AUTOSAR XML (schema 4-2-2)
package /AUTOLIV/SoftwareComponents/SCM
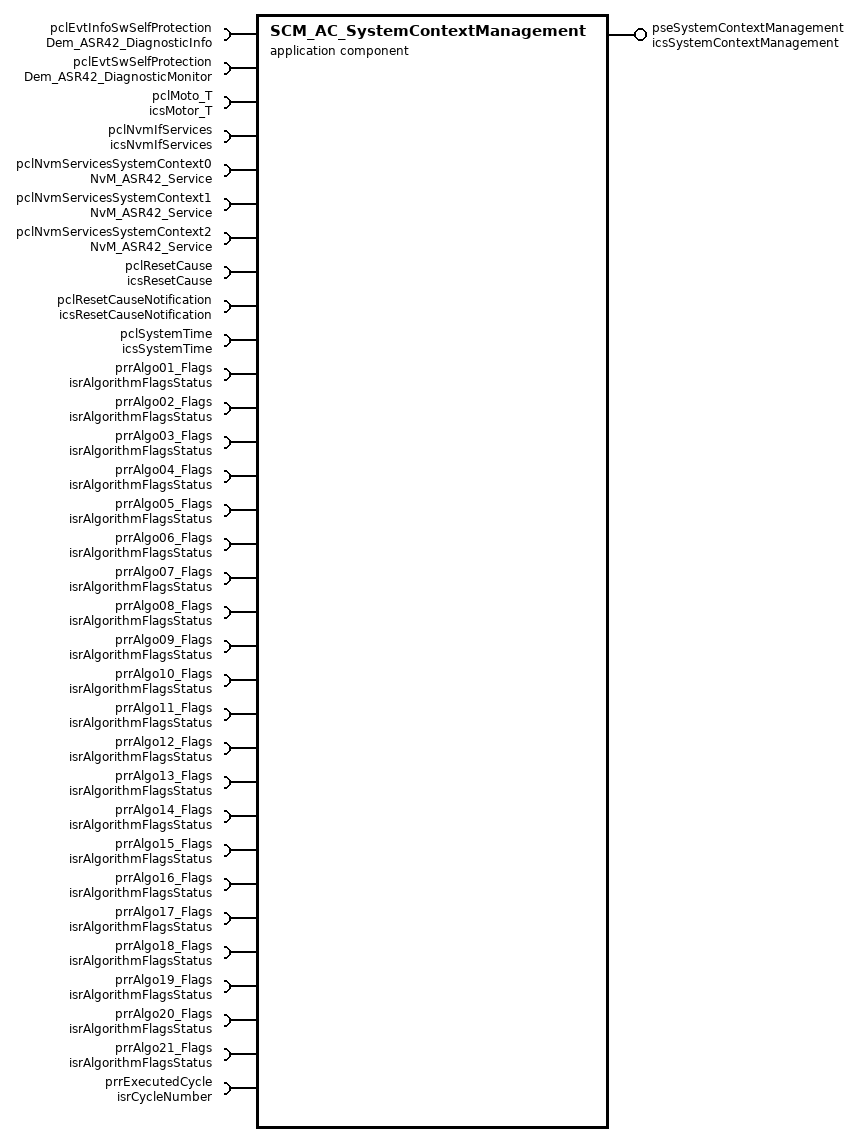
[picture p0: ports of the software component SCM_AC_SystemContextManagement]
  application sw component type SCM_AC_SystemContextManagement: category=SWC
    32 x require port:
      pclEvtInfoSwSelfProtection: required-interface=Dem_ASR42_DiagnosticInfo
        required-com-specs:
          GetEventStatus
          GetEventFailed
          GetEventTested
          GetDTCOfEvent
          GetFaultDetectionCounter
          GetEventFreezeFrameData
          GetEventExtendedDataRecord
      pclEvtSwSelfProtection: required-com-specs=[SetEventStatus, ResetEventStatus, PrestoreFreezeFrame, ClearPrestoredFreezeFrame], required-interface=Dem_ASR42_DiagnosticMonitor
      pclMoto_T: required-com-specs=[GetDeficiencyLevel, InitializeDeficiencyLevel], required-interface=icsMotor_T
      pclNvmIfServices: required-com-specs=[GetNvmBlockStatus, GetNvmBlockLength, SynchronousRecord], required-interface=icsNvmIfServices
      pclNvmServicesSystemContext0: required-interface=NvM_ASR42_Service
        required-com-specs:
          GetErrorStatus
          SetDataIndex
          GetDataIndex
          SetRamBlockStatus
          ReadBlock
          WriteBlock
          RestoreBlockDefaults
          EraseBlock
          InvalidateNvBlock
      pclNvmServicesSystemContext1: required-interface=NvM_ASR42_Service
        required-com-specs:
          GetErrorStatus
          SetDataIndex
          GetDataIndex
          SetRamBlockStatus
          ReadBlock
          WriteBlock
          RestoreBlockDefaults
          EraseBlock
          InvalidateNvBlock
      pclNvmServicesSystemContext2: required-interface=NvM_ASR42_Service
        required-com-specs:
          GetErrorStatus
          SetDataIndex
          GetDataIndex
          SetRamBlockStatus
          ReadBlock
          WriteBlock
          RestoreBlockDefaults
          EraseBlock
          InvalidateNvBlock
      pclResetCause: client-com-spec=GetResetCause, required-interface=icsResetCause
      pclResetCauseNotification: client-com-spec=NotifyResetCause, required-interface=icsResetCauseNotification
      pclSystemTime: required-com-specs=[ReadRelativeSystemTime, WriteRelativeSystemTime, ReadAbsoluteSystemTime, WriteAbsoluteSystemTime], required-interface=icsSystemTime
      prrAlgo01_Flags: required-interface=isrAlgorithmFlagsStatus
        required-com-specs:
          data-element=b8TriggerFlag, uses-end-to-end-protection=0, init-value=constant-reference=APPLINIT_KB8_ALGO_FLAG_FALSE
          data-element=b8InterruptFlag, uses-end-to-end-protection=0, init-value=constant-reference=APPLINIT_KB8_ALGO_FLAG_FALSE
          data-element=b8PreActivationFlag, uses-end-to-end-protection=0, init-value=constant-reference=APPLINIT_KB8_ALGO_FLAG_FALSE
          data-element=b8PreConditionsFlag, uses-end-to-end-protection=0, init-value=constant-reference=APPLINIT_KB8_ALGO_FLAG_FALSE
          data-element=u8TriggeringSource, uses-end-to-end-protection=0, init-value=constant-reference=APPLINIT_KU8_TRIGGERING_SOURCE_NO
      prrAlgo02_Flags: required-interface=isrAlgorithmFlagsStatus
        required-com-specs:
          data-element=b8TriggerFlag, uses-end-to-end-protection=0, init-value=constant-reference=APPLINIT_KB8_ALGO_FLAG_FALSE
          data-element=b8InterruptFlag, uses-end-to-end-protection=0, init-value=constant-reference=APPLINIT_KB8_ALGO_FLAG_FALSE
          data-element=b8PreActivationFlag, uses-end-to-end-protection=0, init-value=constant-reference=APPLINIT_KB8_ALGO_FLAG_FALSE
          data-element=b8PreConditionsFlag, uses-end-to-end-protection=0, init-value=constant-reference=APPLINIT_KB8_ALGO_FLAG_FALSE
          data-element=u8TriggeringSource, uses-end-to-end-protection=0, init-value=constant-reference=APPLINIT_KU8_TRIGGERING_SOURCE_NO
      prrAlgo03_Flags: required-interface=isrAlgorithmFlagsStatus
        required-com-specs:
          data-element=b8TriggerFlag, uses-end-to-end-protection=0, init-value=constant-reference=APPLINIT_KB8_ALGO_FLAG_FALSE
          data-element=b8InterruptFlag, uses-end-to-end-protection=0, init-value=constant-reference=APPLINIT_KB8_ALGO_FLAG_FALSE
          data-element=b8PreActivationFlag, uses-end-to-end-protection=0, init-value=constant-reference=APPLINIT_KB8_ALGO_FLAG_FALSE
          data-element=b8PreConditionsFlag, uses-end-to-end-protection=0, init-value=constant-reference=APPLINIT_KB8_ALGO_FLAG_FALSE
          data-element=u8TriggeringSource, uses-end-to-end-protection=0, init-value=constant-reference=APPLINIT_KU8_TRIGGERING_SOURCE_NO
      prrAlgo04_Flags: required-interface=isrAlgorithmFlagsStatus
        required-com-specs:
          data-element=b8TriggerFlag, uses-end-to-end-protection=0, init-value=constant-reference=APPLINIT_KB8_ALGO_FLAG_FALSE
          data-element=b8InterruptFlag, uses-end-to-end-protection=0, init-value=constant-reference=APPLINIT_KB8_ALGO_FLAG_FALSE
          data-element=b8PreActivationFlag, uses-end-to-end-protection=0, init-value=constant-reference=APPLINIT_KB8_ALGO_FLAG_FALSE
          data-element=b8PreConditionsFlag, uses-end-to-end-protection=0, init-value=constant-reference=APPLINIT_KB8_ALGO_FLAG_FALSE
          data-element=u8TriggeringSource, uses-end-to-end-protection=0, init-value=constant-reference=APPLINIT_KU8_TRIGGERING_SOURCE_NO
      prrAlgo05_Flags: required-interface=isrAlgorithmFlagsStatus
        required-com-specs:
          data-element=b8TriggerFlag, uses-end-to-end-protection=0, init-value=constant-reference=APPLINIT_KB8_ALGO_FLAG_FALSE
          data-element=b8InterruptFlag, uses-end-to-end-protection=0, init-value=constant-reference=APPLINIT_KB8_ALGO_FLAG_FALSE
          data-element=b8PreActivationFlag, uses-end-to-end-protection=0, init-value=constant-reference=APPLINIT_KB8_ALGO_FLAG_FALSE
          data-element=b8PreConditionsFlag, uses-end-to-end-protection=0, init-value=constant-reference=APPLINIT_KB8_ALGO_FLAG_FALSE
          data-element=u8TriggeringSource, uses-end-to-end-protection=0, init-value=constant-reference=APPLINIT_KU8_TRIGGERING_SOURCE_NO
      prrAlgo06_Flags: required-interface=isrAlgorithmFlagsStatus
        required-com-specs:
          data-element=b8TriggerFlag, uses-end-to-end-protection=0, init-value=constant-reference=APPLINIT_KB8_ALGO_FLAG_FALSE
          data-element=b8InterruptFlag, uses-end-to-end-protection=0, init-value=constant-reference=APPLINIT_KB8_ALGO_FLAG_FALSE
          data-element=b8PreActivationFlag, uses-end-to-end-protection=0, init-value=constant-reference=APPLINIT_KB8_ALGO_FLAG_FALSE
          data-element=b8PreConditionsFlag, uses-end-to-end-protection=0, init-value=constant-reference=APPLINIT_KB8_ALGO_FLAG_FALSE
          data-element=u8TriggeringSource, uses-end-to-end-protection=0, init-value=constant-reference=APPLINIT_KU8_TRIGGERING_SOURCE_NO
      prrAlgo07_Flags: required-interface=isrAlgorithmFlagsStatus
        required-com-specs:
          data-element=b8TriggerFlag, uses-end-to-end-protection=0, init-value=constant-reference=APPLINIT_KB8_ALGO_FLAG_FALSE
          data-element=b8InterruptFlag, uses-end-to-end-protection=0, init-value=constant-reference=APPLINIT_KB8_ALGO_FLAG_FALSE
          data-element=b8PreActivationFlag, uses-end-to-end-protection=0, init-value=constant-reference=APPLINIT_KB8_ALGO_FLAG_FALSE
          data-element=b8PreConditionsFlag, uses-end-to-end-protection=0, init-value=constant-reference=APPLINIT_KB8_ALGO_FLAG_FALSE
          data-element=u8TriggeringSource, uses-end-to-end-protection=0, init-value=constant-reference=APPLINIT_KU8_TRIGGERING_SOURCE_NO
      prrAlgo08_Flags: required-interface=isrAlgorithmFlagsStatus
        required-com-specs:
          data-element=b8TriggerFlag, uses-end-to-end-protection=0, init-value=constant-reference=APPLINIT_KB8_ALGO_FLAG_FALSE
          data-element=b8InterruptFlag, uses-end-to-end-protection=0, init-value=constant-reference=APPLINIT_KB8_ALGO_FLAG_FALSE
          data-element=b8PreActivationFlag, uses-end-to-end-protection=0, init-value=constant-reference=APPLINIT_KB8_ALGO_FLAG_FALSE
          data-element=b8PreConditionsFlag, uses-end-to-end-protection=0, init-value=constant-reference=APPLINIT_KB8_ALGO_FLAG_FALSE
          data-element=u8TriggeringSource, uses-end-to-end-protection=0, init-value=constant-reference=APPLINIT_KU8_TRIGGERING_SOURCE_NO
      prrAlgo09_Flags: required-interface=isrAlgorithmFlagsStatus
        required-com-specs:
          data-element=b8TriggerFlag, uses-end-to-end-protection=0, init-value=constant-reference=APPLINIT_KB8_ALGO_FLAG_FALSE
          data-element=b8InterruptFlag, uses-end-to-end-protection=0, init-value=constant-reference=APPLINIT_KB8_ALGO_FLAG_FALSE
          data-element=b8PreActivationFlag, uses-end-to-end-protection=0, init-value=constant-reference=APPLINIT_KB8_ALGO_FLAG_FALSE
          data-element=b8PreConditionsFlag, uses-end-to-end-protection=0, init-value=constant-reference=APPLINIT_KB8_ALGO_FLAG_FALSE
          data-element=u8TriggeringSource, uses-end-to-end-protection=0, init-value=constant-reference=APPLINIT_KU8_TRIGGERING_SOURCE_NO
      prrAlgo10_Flags: required-interface=isrAlgorithmFlagsStatus
        required-com-specs:
          data-element=b8TriggerFlag, uses-end-to-end-protection=0, init-value=constant-reference=APPLINIT_KB8_ALGO_FLAG_FALSE
          data-element=b8InterruptFlag, uses-end-to-end-protection=0, init-value=constant-reference=APPLINIT_KB8_ALGO_FLAG_FALSE
          data-element=b8PreActivationFlag, uses-end-to-end-protection=0, init-value=constant-reference=APPLINIT_KB8_ALGO_FLAG_FALSE
          data-element=b8PreConditionsFlag, uses-end-to-end-protection=0, init-value=constant-reference=APPLINIT_KB8_ALGO_FLAG_FALSE
          data-element=u8TriggeringSource, uses-end-to-end-protection=0, init-value=constant-reference=APPLINIT_KU8_TRIGGERING_SOURCE_NO
      prrAlgo11_Flags: required-interface=isrAlgorithmFlagsStatus
        required-com-specs:
          data-element=b8TriggerFlag, uses-end-to-end-protection=0, init-value=constant-reference=APPLINIT_KB8_ALGO_FLAG_FALSE
          data-element=b8InterruptFlag, uses-end-to-end-protection=0, init-value=constant-reference=APPLINIT_KB8_ALGO_FLAG_FALSE
          data-element=b8PreActivationFlag, uses-end-to-end-protection=0, init-value=constant-reference=APPLINIT_KB8_ALGO_FLAG_FALSE
          data-element=b8PreConditionsFlag, uses-end-to-end-protection=0, init-value=constant-reference=APPLINIT_KB8_ALGO_FLAG_FALSE
          data-element=u8TriggeringSource, uses-end-to-end-protection=0, init-value=constant-reference=APPLINIT_KU8_TRIGGERING_SOURCE_NO
      prrAlgo12_Flags: required-interface=isrAlgorithmFlagsStatus
        required-com-specs:
          data-element=b8TriggerFlag, uses-end-to-end-protection=0, init-value=constant-reference=APPLINIT_KB8_ALGO_FLAG_FALSE
          data-element=b8InterruptFlag, uses-end-to-end-protection=0, init-value=constant-reference=APPLINIT_KB8_ALGO_FLAG_FALSE
          data-element=b8PreActivationFlag, uses-end-to-end-protection=0, init-value=constant-reference=APPLINIT_KB8_ALGO_FLAG_FALSE
          data-element=b8PreConditionsFlag, uses-end-to-end-protection=0, init-value=constant-reference=APPLINIT_KB8_ALGO_FLAG_FALSE
          data-element=u8TriggeringSource, uses-end-to-end-protection=0, init-value=constant-reference=APPLINIT_KU8_TRIGGERING_SOURCE_NO
      prrAlgo13_Flags: required-interface=isrAlgorithmFlagsStatus
        required-com-specs:
          data-element=b8TriggerFlag, uses-end-to-end-protection=0, init-value=constant-reference=APPLINIT_KB8_ALGO_FLAG_FALSE
          data-element=b8InterruptFlag, uses-end-to-end-protection=0, init-value=constant-reference=APPLINIT_KB8_ALGO_FLAG_FALSE
          data-element=b8PreActivationFlag, uses-end-to-end-protection=0, init-value=constant-reference=APPLINIT_KB8_ALGO_FLAG_FALSE
          data-element=b8PreConditionsFlag, uses-end-to-end-protection=0, init-value=constant-reference=APPLINIT_KB8_ALGO_FLAG_FALSE
          data-element=u8TriggeringSource, uses-end-to-end-protection=0, init-value=constant-reference=APPLINIT_KU8_TRIGGERING_SOURCE_NO
      prrAlgo14_Flags: required-interface=isrAlgorithmFlagsStatus
        required-com-specs:
          data-element=b8TriggerFlag, uses-end-to-end-protection=0, init-value=constant-reference=APPLINIT_KB8_ALGO_FLAG_FALSE
          data-element=b8InterruptFlag, uses-end-to-end-protection=0, init-value=constant-reference=APPLINIT_KB8_ALGO_FLAG_FALSE
          data-element=b8PreActivationFlag, uses-end-to-end-protection=0, init-value=constant-reference=APPLINIT_KB8_ALGO_FLAG_FALSE
          data-element=b8PreConditionsFlag, uses-end-to-end-protection=0, init-value=constant-reference=APPLINIT_KB8_ALGO_FLAG_FALSE
          data-element=u8TriggeringSource, uses-end-to-end-protection=0, init-value=constant-reference=APPLINIT_KU8_TRIGGERING_SOURCE_NO
      prrAlgo15_Flags: required-interface=isrAlgorithmFlagsStatus
        required-com-specs:
          data-element=b8TriggerFlag, uses-end-to-end-protection=0, init-value=constant-reference=APPLINIT_KB8_ALGO_FLAG_FALSE
          data-element=b8InterruptFlag, uses-end-to-end-protection=0, init-value=constant-reference=APPLINIT_KB8_ALGO_FLAG_FALSE
          data-element=b8PreActivationFlag, uses-end-to-end-protection=0, init-value=constant-reference=APPLINIT_KB8_ALGO_FLAG_FALSE
          data-element=b8PreConditionsFlag, uses-end-to-end-protection=0, init-value=constant-reference=APPLINIT_KB8_ALGO_FLAG_FALSE
          data-element=u8TriggeringSource, uses-end-to-end-protection=0, init-value=constant-reference=APPLINIT_KU8_TRIGGERING_SOURCE_NO
      prrAlgo16_Flags: required-interface=isrAlgorithmFlagsStatus
        required-com-specs:
          data-element=b8TriggerFlag, uses-end-to-end-protection=0, init-value=constant-reference=APPLINIT_KB8_ALGO_FLAG_FALSE
          data-element=b8InterruptFlag, uses-end-to-end-protection=0, init-value=constant-reference=APPLINIT_KB8_ALGO_FLAG_FALSE
          data-element=b8PreActivationFlag, uses-end-to-end-protection=0, init-value=constant-reference=APPLINIT_KB8_ALGO_FLAG_FALSE
          data-element=b8PreConditionsFlag, uses-end-to-end-protection=0, init-value=constant-reference=APPLINIT_KB8_ALGO_FLAG_FALSE
          data-element=u8TriggeringSource, uses-end-to-end-protection=0, init-value=constant-reference=APPLINIT_KU8_TRIGGERING_SOURCE_NO
      prrAlgo17_Flags: required-interface=isrAlgorithmFlagsStatus
        required-com-specs:
          data-element=b8TriggerFlag, uses-end-to-end-protection=0, init-value=constant-reference=APPLINIT_KB8_ALGO_FLAG_FALSE
          data-element=b8InterruptFlag, uses-end-to-end-protection=0, init-value=constant-reference=APPLINIT_KB8_ALGO_FLAG_FALSE
          data-element=b8PreActivationFlag, uses-end-to-end-protection=0, init-value=constant-reference=APPLINIT_KB8_ALGO_FLAG_FALSE
          data-element=b8PreConditionsFlag, uses-end-to-end-protection=0, init-value=constant-reference=APPLINIT_KB8_ALGO_FLAG_FALSE
          data-element=u8TriggeringSource, uses-end-to-end-protection=0, init-value=constant-reference=APPLINIT_KU8_TRIGGERING_SOURCE_NO
      prrAlgo18_Flags: required-interface=isrAlgorithmFlagsStatus
        required-com-specs:
          data-element=b8TriggerFlag, uses-end-to-end-protection=0, init-value=constant-reference=APPLINIT_KB8_ALGO_FLAG_FALSE
          data-element=b8InterruptFlag, uses-end-to-end-protection=0, init-value=constant-reference=APPLINIT_KB8_ALGO_FLAG_FALSE
          data-element=b8PreActivationFlag, uses-end-to-end-protection=0, init-value=constant-reference=APPLINIT_KB8_ALGO_FLAG_FALSE
          data-element=b8PreConditionsFlag, uses-end-to-end-protection=0, init-value=constant-reference=APPLINIT_KB8_ALGO_FLAG_FALSE
          data-element=u8TriggeringSource, uses-end-to-end-protection=0, init-value=constant-reference=APPLINIT_KU8_TRIGGERING_SOURCE_NO
      prrAlgo19_Flags: required-interface=isrAlgorithmFlagsStatus
        required-com-specs:
          data-element=b8TriggerFlag, uses-end-to-end-protection=0, init-value=constant-reference=APPLINIT_KB8_ALGO_FLAG_FALSE
          data-element=b8InterruptFlag, uses-end-to-end-protection=0, init-value=constant-reference=APPLINIT_KB8_ALGO_FLAG_FALSE
          data-element=b8PreActivationFlag, uses-end-to-end-protection=0, init-value=constant-reference=APPLINIT_KB8_ALGO_FLAG_FALSE
          data-element=b8PreConditionsFlag, uses-end-to-end-protection=0, init-value=constant-reference=APPLINIT_KB8_ALGO_FLAG_FALSE
          data-element=u8TriggeringSource, uses-end-to-end-protection=0, init-value=constant-reference=APPLINIT_KU8_TRIGGERING_SOURCE_NO
      prrAlgo20_Flags: required-interface=isrAlgorithmFlagsStatus
        required-com-specs:
          data-element=b8TriggerFlag, uses-end-to-end-protection=0, init-value=constant-reference=APPLINIT_KB8_ALGO_FLAG_FALSE
          data-element=b8InterruptFlag, uses-end-to-end-protection=0, init-value=constant-reference=APPLINIT_KB8_ALGO_FLAG_FALSE
          data-element=b8PreActivationFlag, uses-end-to-end-protection=0, init-value=constant-reference=APPLINIT_KB8_ALGO_FLAG_FALSE
          data-element=b8PreConditionsFlag, uses-end-to-end-protection=0, init-value=constant-reference=APPLINIT_KB8_ALGO_FLAG_FALSE
          data-element=u8TriggeringSource, uses-end-to-end-protection=0, init-value=constant-reference=APPLINIT_KU8_TRIGGERING_SOURCE_NO
      prrAlgo21_Flags: required-interface=isrAlgorithmFlagsStatus
        required-com-specs:
          data-element=b8TriggerFlag, uses-end-to-end-protection=0, init-value=constant-reference=APPLINIT_KB8_ALGO_FLAG_FALSE
          data-element=b8InterruptFlag, uses-end-to-end-protection=0, init-value=constant-reference=APPLINIT_KB8_ALGO_FLAG_FALSE
          data-element=b8PreActivationFlag, uses-end-to-end-protection=0, init-value=constant-reference=APPLINIT_KB8_ALGO_FLAG_FALSE
          data-element=b8PreConditionsFlag, uses-end-to-end-protection=0, init-value=constant-reference=APPLINIT_KB8_ALGO_FLAG_FALSE
          data-element=u8TriggeringSource, uses-end-to-end-protection=0, init-value=constant-reference=APPLINIT_KU8_TRIGGERING_SOURCE_NO
      prrExecutedCycle: nonqueued-receiver-com-spec{data-element=u8CycleNumber, uses-end-to-end-protection=0, init-value=constant-reference=APPLINIT_KU8_CYCLE_NUMBER_NONE}, required-interface=isrCycleNumber
    provide port pseSystemContextManagement: provided-interface=icsSystemContextManagement
      provided-com-specs:
        operation=GetLastTensionningState, queue-length=1
        operation=RestoreSystemContext, queue-length=1
        operation=GetLastKL30LostStatus, queue-length=1
        operation=SuperviseKL30bg, queue-length=1
        operation=ManageSystemContextStorage, queue-length=1
